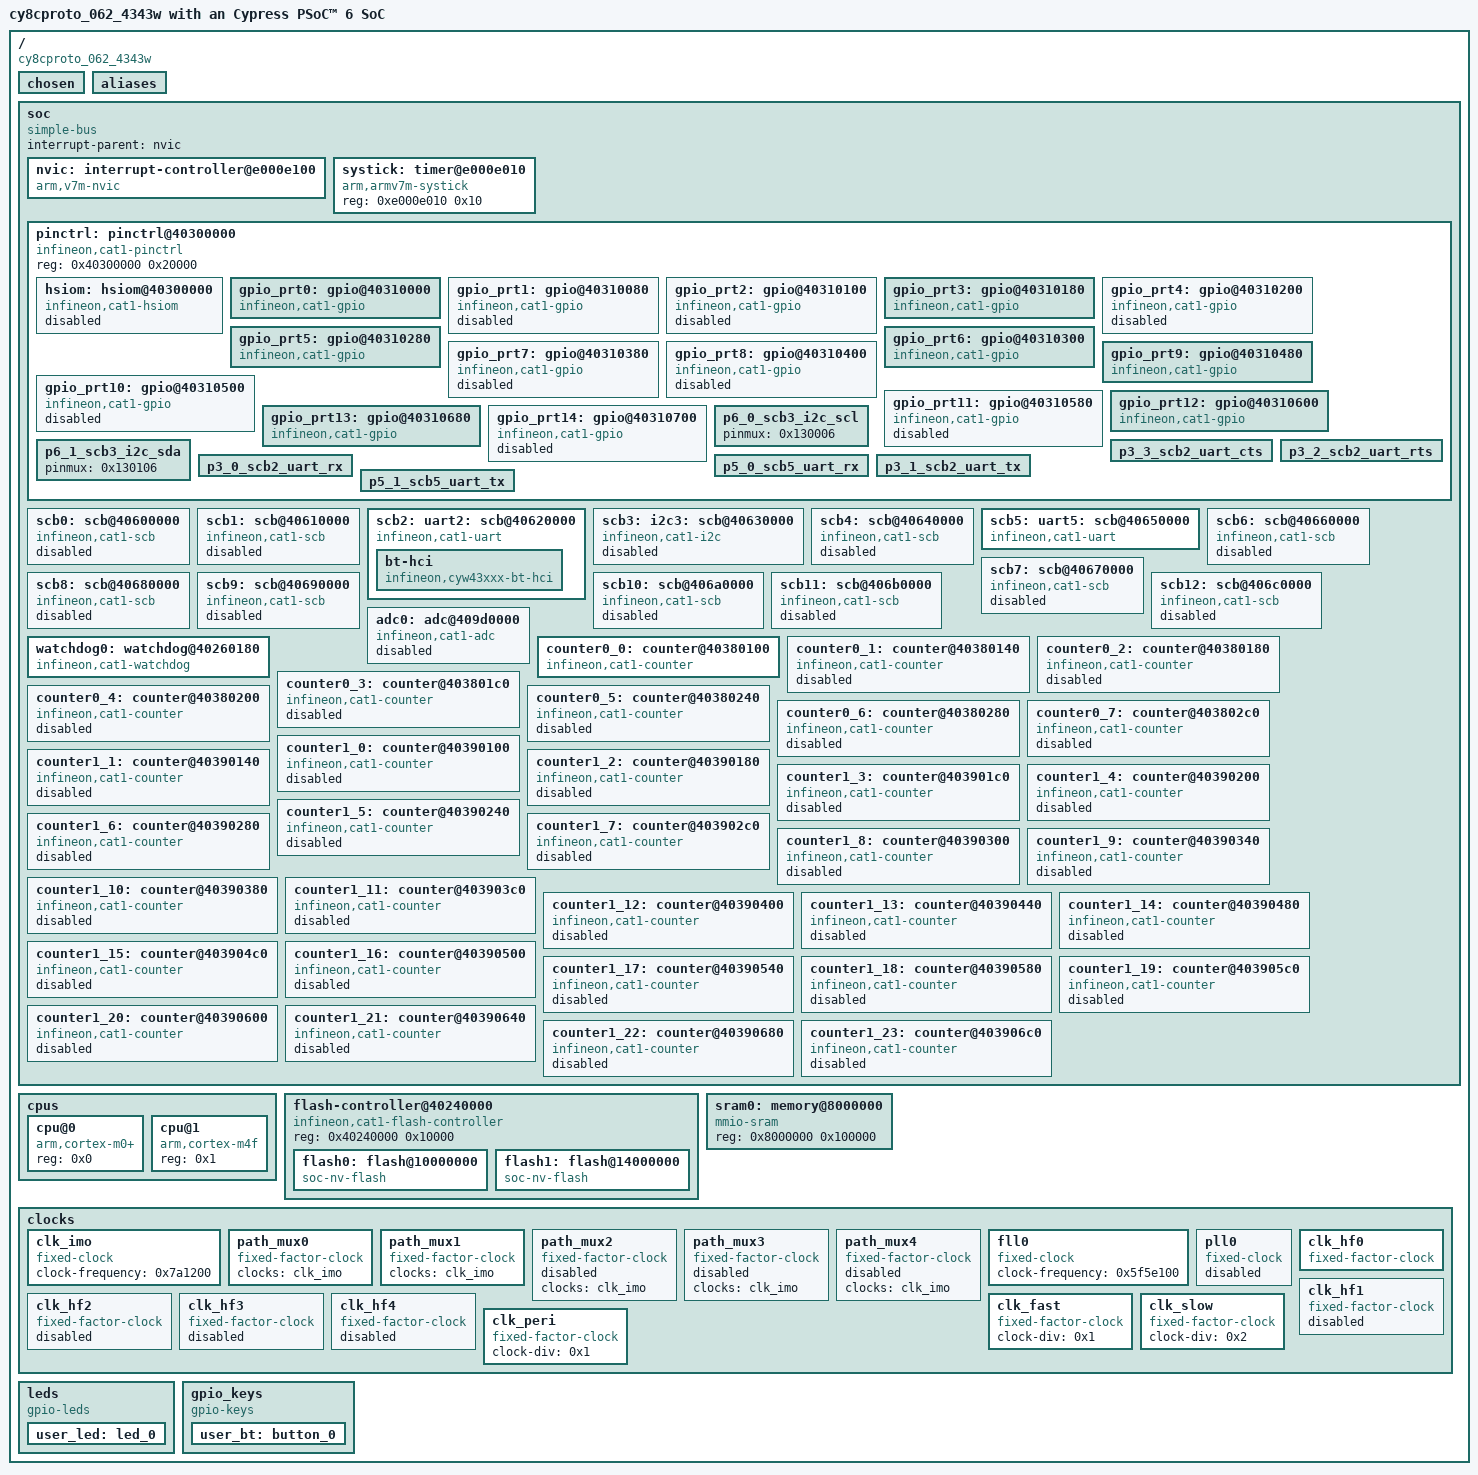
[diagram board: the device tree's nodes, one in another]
/dts-v1/;

/ {
	#address-cells = < 0x1 >;
	#size-cells = < 0x1 >;
	model = "cy8cproto_062_4343w with an Cypress PSoC™ 6 SoC";
	compatible = "cy8cproto_062_4343w", "PSoC6";
	chosen {
		zephyr,sram = &sram0;
		zephyr,flash = &flash0;
		zephyr,console = &uart5;
		zephyr,shell-uart = &uart5;
		zephyr,bt_uart = &uart2;
	};
	aliases {
		led0 = &user_led;
		sw0 = &user_bt;
		uart-5 = &uart5;
		i2c-0 = &i2c3;
		watchdog0 = &watchdog0;
	};
	soc {
		#address-cells = < 0x1 >;
		#size-cells = < 0x1 >;
		compatible = "simple-bus";
		interrupt-parent = < &nvic >;
		ranges;
		nvic: interrupt-controller@e000e100 {
			#address-cells = < 0x1 >;
			compatible = "arm,v7m-nvic";
			reg = < 0xe000e100 0xc00 >;
			interrupt-controller;
			#interrupt-cells = < 0x2 >;
			arm,num-irq-priority-bits = < 0x3 >;
			phandle = < 0x1 >;
		};
		systick: timer@e000e010 {
			compatible = "arm,armv7m-systick";
			reg = < 0xe000e010 0x10 >;
		};
		pinctrl: pinctrl@40300000 {
			compatible = "infineon,cat1-pinctrl";
			reg = < 0x40300000 0x20000 >;
			#address-cells = < 0x1 >;
			#size-cells = < 0x0 >;
			hsiom: hsiom@40300000 {
				compatible = "infineon,cat1-hsiom";
				reg = < 0x40300000 0x4000 >;
				interrupts = < 0xf 0x6 >, < 0x10 0x6 >;
				status = "disabled";
			};
			gpio_prt0: gpio@40310000 {
				compatible = "infineon,cat1-gpio";
				reg = < 0x40310000 0x80 >;
				interrupts = < 0x0 0x6 >;
				gpio-controller;
				ngpios = < 0x6 >;
				status = "okay";
				#gpio-cells = < 0x2 >;
				phandle = < 0x12 >;
			};
			gpio_prt1: gpio@40310080 {
				compatible = "infineon,cat1-gpio";
				reg = < 0x40310080 0x80 >;
				interrupts = < 0x1 0x6 >;
				gpio-controller;
				ngpios = < 0x6 >;
				status = "disabled";
				#gpio-cells = < 0x2 >;
			};
			gpio_prt2: gpio@40310100 {
				compatible = "infineon,cat1-gpio";
				reg = < 0x40310100 0x80 >;
				interrupts = < 0x2 0x6 >;
				gpio-controller;
				ngpios = < 0x8 >;
				status = "disabled";
				#gpio-cells = < 0x2 >;
			};
			gpio_prt3: gpio@40310180 {
				compatible = "infineon,cat1-gpio";
				reg = < 0x40310180 0x80 >;
				interrupts = < 0x3 0x6 >;
				gpio-controller;
				ngpios = < 0x6 >;
				status = "okay";
				#gpio-cells = < 0x2 >;
				phandle = < 0x6 >;
			};
			gpio_prt4: gpio@40310200 {
				compatible = "infineon,cat1-gpio";
				reg = < 0x40310200 0x80 >;
				interrupts = < 0x4 0x6 >;
				gpio-controller;
				ngpios = < 0x2 >;
				status = "disabled";
				#gpio-cells = < 0x2 >;
			};
			gpio_prt5: gpio@40310280 {
				compatible = "infineon,cat1-gpio";
				reg = < 0x40310280 0x80 >;
				interrupts = < 0x5 0x6 >;
				gpio-controller;
				ngpios = < 0x8 >;
				status = "okay";
				#gpio-cells = < 0x2 >;
			};
			gpio_prt6: gpio@40310300 {
				compatible = "infineon,cat1-gpio";
				reg = < 0x40310300 0x80 >;
				interrupts = < 0x6 0x6 >;
				gpio-controller;
				ngpios = < 0x8 >;
				status = "okay";
				#gpio-cells = < 0x2 >;
			};
			gpio_prt7: gpio@40310380 {
				compatible = "infineon,cat1-gpio";
				reg = < 0x40310380 0x80 >;
				interrupts = < 0x7 0x6 >;
				gpio-controller;
				ngpios = < 0x8 >;
				status = "disabled";
				#gpio-cells = < 0x2 >;
			};
			gpio_prt8: gpio@40310400 {
				compatible = "infineon,cat1-gpio";
				reg = < 0x40310400 0x80 >;
				interrupts = < 0x8 0x6 >;
				gpio-controller;
				ngpios = < 0x8 >;
				status = "disabled";
				#gpio-cells = < 0x2 >;
			};
			gpio_prt9: gpio@40310480 {
				compatible = "infineon,cat1-gpio";
				reg = < 0x40310480 0x80 >;
				interrupts = < 0x9 0x6 >;
				gpio-controller;
				ngpios = < 0x8 >;
				status = "okay";
				#gpio-cells = < 0x2 >;
			};
			gpio_prt10: gpio@40310500 {
				compatible = "infineon,cat1-gpio";
				reg = < 0x40310500 0x80 >;
				interrupts = < 0xa 0x6 >;
				gpio-controller;
				ngpios = < 0x8 >;
				status = "disabled";
				#gpio-cells = < 0x2 >;
			};
			gpio_prt11: gpio@40310580 {
				compatible = "infineon,cat1-gpio";
				reg = < 0x40310580 0x80 >;
				interrupts = < 0xb 0x6 >;
				gpio-controller;
				ngpios = < 0x8 >;
				status = "disabled";
				#gpio-cells = < 0x2 >;
			};
			gpio_prt12: gpio@40310600 {
				compatible = "infineon,cat1-gpio";
				reg = < 0x40310600 0x80 >;
				interrupts = < 0xc 0x6 >;
				gpio-controller;
				ngpios = < 0x8 >;
				status = "okay";
				#gpio-cells = < 0x2 >;
			};
			gpio_prt13: gpio@40310680 {
				compatible = "infineon,cat1-gpio";
				reg = < 0x40310680 0x80 >;
				interrupts = < 0xd 0x6 >;
				gpio-controller;
				ngpios = < 0x8 >;
				status = "okay";
				#gpio-cells = < 0x2 >;
				phandle = < 0x11 >;
			};
			gpio_prt14: gpio@40310700 {
				compatible = "infineon,cat1-gpio";
				reg = < 0x40310700 0x80 >;
				interrupts = < 0xe 0x6 >;
				gpio-controller;
				ngpios = < 0x2 >;
				status = "disabled";
				#gpio-cells = < 0x2 >;
			};
			p6_0_scb3_i2c_scl: p6_0_scb3_i2c_scl {
				pinmux = < 0x130006 >;
				phandle = < 0x7 >;
			};
			p6_1_scb3_i2c_sda: p6_1_scb3_i2c_sda {
				pinmux = < 0x130106 >;
				phandle = < 0x8 >;
			};
			p3_3_scb2_uart_cts: p3_3_scb2_uart_cts {
				pinmux = < 0x120303 >;
				input-enable;
				phandle = < 0x5 >;
			};
			p3_2_scb2_uart_rts: p3_2_scb2_uart_rts {
				pinmux = < 0x120203 >;
				drive-push-pull;
				phandle = < 0x4 >;
			};
			p3_0_scb2_uart_rx: p3_0_scb2_uart_rx {
				pinmux = < 0x120003 >;
				input-enable;
				phandle = < 0x3 >;
			};
			p5_0_scb5_uart_rx: p5_0_scb5_uart_rx {
				pinmux = < 0x120005 >;
				input-enable;
				phandle = < 0xa >;
			};
			p3_1_scb2_uart_tx: p3_1_scb2_uart_tx {
				pinmux = < 0x120103 >;
				drive-push-pull;
				phandle = < 0x2 >;
			};
			p5_1_scb5_uart_tx: p5_1_scb5_uart_tx {
				pinmux = < 0x120105 >;
				drive-push-pull;
				phandle = < 0x9 >;
			};
		};
		scb0: scb@40600000 {
			compatible = "infineon,cat1-scb";
			reg = < 0x40600000 0x10000 >;
			#address-cells = < 0x1 >;
			#size-cells = < 0x0 >;
			interrupts = < 0x27 0x6 >;
			status = "disabled";
		};
		scb1: scb@40610000 {
			compatible = "infineon,cat1-scb";
			reg = < 0x40610000 0x10000 >;
			#address-cells = < 0x1 >;
			#size-cells = < 0x0 >;
			interrupts = < 0x28 0x6 >;
			status = "disabled";
		};
		scb2: uart2: scb@40620000 {
			compatible = "infineon,cat1-uart";
			reg = < 0x40620000 0x10000 >;
			#address-cells = < 0x1 >;
			#size-cells = < 0x0 >;
			interrupts = < 0x29 0x6 >;
			status = "okay";
			current-speed = < 0x1c200 >;
			pinctrl-0 = < &p3_1_scb2_uart_tx &p3_0_scb2_uart_rx &p3_2_scb2_uart_rts &p3_3_scb2_uart_cts >;
			pinctrl-names = "default";
			bt-hci {
				status = "okay";
				compatible = "infineon,cyw43xxx-bt-hci";
				bt-reg-on-gpios = < &gpio_prt3 0x4 0x0 >;
				fw-download-speed = < 0x2dc6c0 >;
			};
		};
		scb3: i2c3: scb@40630000 {
			compatible = "infineon,cat1-i2c";
			reg = < 0x40630000 0x10000 >;
			#address-cells = < 0x1 >;
			#size-cells = < 0x0 >;
			interrupts = < 0x2a 0x6 >;
			status = "disabled";
			pinctrl-0 = < &p6_0_scb3_i2c_scl &p6_1_scb3_i2c_sda >;
			pinctrl-names = "default";
		};
		scb4: scb@40640000 {
			compatible = "infineon,cat1-scb";
			reg = < 0x40640000 0x10000 >;
			#address-cells = < 0x1 >;
			#size-cells = < 0x0 >;
			interrupts = < 0x2b 0x6 >;
			status = "disabled";
		};
		scb5: uart5: scb@40650000 {
			compatible = "infineon,cat1-uart";
			reg = < 0x40650000 0x10000 >;
			#address-cells = < 0x1 >;
			#size-cells = < 0x0 >;
			interrupts = < 0x2c 0x6 >;
			status = "okay";
			current-speed = < 0x1c200 >;
			pinctrl-0 = < &p5_1_scb5_uart_tx &p5_0_scb5_uart_rx >;
			pinctrl-names = "default";
		};
		scb6: scb@40660000 {
			compatible = "infineon,cat1-scb";
			reg = < 0x40660000 0x10000 >;
			#address-cells = < 0x1 >;
			#size-cells = < 0x0 >;
			interrupts = < 0x2d 0x6 >;
			status = "disabled";
		};
		scb7: scb@40670000 {
			compatible = "infineon,cat1-scb";
			reg = < 0x40670000 0x10000 >;
			#address-cells = < 0x1 >;
			#size-cells = < 0x0 >;
			interrupts = < 0x2e 0x6 >;
			status = "disabled";
		};
		scb8: scb@40680000 {
			compatible = "infineon,cat1-scb";
			reg = < 0x40680000 0x10000 >;
			#address-cells = < 0x1 >;
			#size-cells = < 0x0 >;
			interrupts = < 0x12 0x6 >;
			status = "disabled";
		};
		scb9: scb@40690000 {
			compatible = "infineon,cat1-scb";
			reg = < 0x40690000 0x10000 >;
			#address-cells = < 0x1 >;
			#size-cells = < 0x0 >;
			interrupts = < 0x2f 0x6 >;
			status = "disabled";
		};
		scb10: scb@406a0000 {
			compatible = "infineon,cat1-scb";
			reg = < 0x406a0000 0x10000 >;
			#address-cells = < 0x1 >;
			#size-cells = < 0x0 >;
			interrupts = < 0x30 0x6 >;
			status = "disabled";
		};
		scb11: scb@406b0000 {
			compatible = "infineon,cat1-scb";
			reg = < 0x406b0000 0x10000 >;
			#address-cells = < 0x1 >;
			#size-cells = < 0x0 >;
			interrupts = < 0x31 0x6 >;
			status = "disabled";
		};
		scb12: scb@406c0000 {
			compatible = "infineon,cat1-scb";
			reg = < 0x406c0000 0x10000 >;
			#address-cells = < 0x1 >;
			#size-cells = < 0x0 >;
			interrupts = < 0x32 0x6 >;
			status = "disabled";
		};
		adc0: adc@409d0000 {
			compatible = "infineon,cat1-adc";
			reg = < 0x409d0000 0x10000 >;
			interrupts = < 0x9b 0x6 >;
			status = "disabled";
			#io-channel-cells = < 0x1 >;
		};
		watchdog0: watchdog@40260180 {
			compatible = "infineon,cat1-watchdog";
			reg = < 0x40260180 0xc >;
			interrupts = < 0x16 0x6 >;
			status = "okay";
		};
		counter0_0: counter@40380100 {
			compatible = "infineon,cat1-counter";
			reg = < 0x40380100 0x40 >;
			interrupts = < 0x7b 0x6 >;
			resolution = < 0x20 >;
			status = "okay";
		};
		counter0_1: counter@40380140 {
			compatible = "infineon,cat1-counter";
			reg = < 0x40380140 0x40 >;
			interrupts = < 0x7c 0x6 >;
			resolution = < 0x20 >;
			status = "disabled";
		};
		counter0_2: counter@40380180 {
			compatible = "infineon,cat1-counter";
			reg = < 0x40380180 0x40 >;
			interrupts = < 0x7d 0x6 >;
			resolution = < 0x20 >;
			status = "disabled";
		};
		counter0_3: counter@403801c0 {
			compatible = "infineon,cat1-counter";
			reg = < 0x403801c0 0x40 >;
			interrupts = < 0x7e 0x6 >;
			resolution = < 0x20 >;
			status = "disabled";
		};
		counter0_4: counter@40380200 {
			compatible = "infineon,cat1-counter";
			reg = < 0x40380200 0x40 >;
			interrupts = < 0x7f 0x6 >;
			resolution = < 0x20 >;
			status = "disabled";
		};
		counter0_5: counter@40380240 {
			compatible = "infineon,cat1-counter";
			reg = < 0x40380240 0x40 >;
			interrupts = < 0x80 0x6 >;
			resolution = < 0x20 >;
			status = "disabled";
		};
		counter0_6: counter@40380280 {
			compatible = "infineon,cat1-counter";
			reg = < 0x40380280 0x40 >;
			interrupts = < 0x81 0x6 >;
			resolution = < 0x20 >;
			status = "disabled";
		};
		counter0_7: counter@403802c0 {
			compatible = "infineon,cat1-counter";
			reg = < 0x403802c0 0x40 >;
			interrupts = < 0x82 0x6 >;
			resolution = < 0x20 >;
			status = "disabled";
		};
		counter1_0: counter@40390100 {
			compatible = "infineon,cat1-counter";
			reg = < 0x40390100 0x40 >;
			interrupts = < 0x83 0x6 >;
			resolution = < 0x10 >;
			status = "disabled";
		};
		counter1_1: counter@40390140 {
			compatible = "infineon,cat1-counter";
			reg = < 0x40390140 0x40 >;
			interrupts = < 0x84 0x6 >;
			resolution = < 0x10 >;
			status = "disabled";
		};
		counter1_2: counter@40390180 {
			compatible = "infineon,cat1-counter";
			reg = < 0x40390180 0x40 >;
			interrupts = < 0x85 0x6 >;
			resolution = < 0x10 >;
			status = "disabled";
		};
		counter1_3: counter@403901c0 {
			compatible = "infineon,cat1-counter";
			reg = < 0x403901c0 0x40 >;
			interrupts = < 0x86 0x6 >;
			resolution = < 0x10 >;
			status = "disabled";
		};
		counter1_4: counter@40390200 {
			compatible = "infineon,cat1-counter";
			reg = < 0x40390200 0x40 >;
			interrupts = < 0x87 0x6 >;
			resolution = < 0x10 >;
			status = "disabled";
		};
		counter1_5: counter@40390240 {
			compatible = "infineon,cat1-counter";
			reg = < 0x40390240 0x40 >;
			interrupts = < 0x88 0x6 >;
			resolution = < 0x10 >;
			status = "disabled";
		};
		counter1_6: counter@40390280 {
			compatible = "infineon,cat1-counter";
			reg = < 0x40390280 0x40 >;
			interrupts = < 0x89 0x6 >;
			resolution = < 0x10 >;
			status = "disabled";
		};
		counter1_7: counter@403902c0 {
			compatible = "infineon,cat1-counter";
			reg = < 0x403902c0 0x40 >;
			interrupts = < 0x8a 0x6 >;
			resolution = < 0x10 >;
			status = "disabled";
		};
		counter1_8: counter@40390300 {
			compatible = "infineon,cat1-counter";
			reg = < 0x40390300 0x40 >;
			interrupts = < 0x8b 0x6 >;
			resolution = < 0x10 >;
			status = "disabled";
		};
		counter1_9: counter@40390340 {
			compatible = "infineon,cat1-counter";
			reg = < 0x40390340 0x40 >;
			interrupts = < 0x8c 0x6 >;
			resolution = < 0x10 >;
			status = "disabled";
		};
		counter1_10: counter@40390380 {
			compatible = "infineon,cat1-counter";
			reg = < 0x40390380 0x40 >;
			interrupts = < 0x8d 0x6 >;
			resolution = < 0x10 >;
			status = "disabled";
		};
		counter1_11: counter@403903c0 {
			compatible = "infineon,cat1-counter";
			reg = < 0x403903c0 0x40 >;
			interrupts = < 0x8e 0x6 >;
			resolution = < 0x10 >;
			status = "disabled";
		};
		counter1_12: counter@40390400 {
			compatible = "infineon,cat1-counter";
			reg = < 0x40390400 0x40 >;
			interrupts = < 0x8f 0x6 >;
			resolution = < 0x10 >;
			status = "disabled";
		};
		counter1_13: counter@40390440 {
			compatible = "infineon,cat1-counter";
			reg = < 0x40390440 0x40 >;
			interrupts = < 0x90 0x6 >;
			resolution = < 0x10 >;
			status = "disabled";
		};
		counter1_14: counter@40390480 {
			compatible = "infineon,cat1-counter";
			reg = < 0x40390480 0x40 >;
			interrupts = < 0x91 0x6 >;
			resolution = < 0x10 >;
			status = "disabled";
		};
		counter1_15: counter@403904c0 {
			compatible = "infineon,cat1-counter";
			reg = < 0x403904c0 0x40 >;
			interrupts = < 0x92 0x6 >;
			resolution = < 0x10 >;
			status = "disabled";
		};
		counter1_16: counter@40390500 {
			compatible = "infineon,cat1-counter";
			reg = < 0x40390500 0x40 >;
			interrupts = < 0x93 0x6 >;
			resolution = < 0x10 >;
			status = "disabled";
		};
		counter1_17: counter@40390540 {
			compatible = "infineon,cat1-counter";
			reg = < 0x40390540 0x40 >;
			interrupts = < 0x94 0x6 >;
			resolution = < 0x10 >;
			status = "disabled";
		};
		counter1_18: counter@40390580 {
			compatible = "infineon,cat1-counter";
			reg = < 0x40390580 0x40 >;
			interrupts = < 0x95 0x6 >;
			resolution = < 0x10 >;
			status = "disabled";
		};
		counter1_19: counter@403905c0 {
			compatible = "infineon,cat1-counter";
			reg = < 0x403905c0 0x40 >;
			interrupts = < 0x96 0x6 >;
			resolution = < 0x10 >;
			status = "disabled";
		};
		counter1_20: counter@40390600 {
			compatible = "infineon,cat1-counter";
			reg = < 0x40390600 0x40 >;
			interrupts = < 0x97 0x6 >;
			resolution = < 0x10 >;
			status = "disabled";
		};
		counter1_21: counter@40390640 {
			compatible = "infineon,cat1-counter";
			reg = < 0x40390640 0x40 >;
			interrupts = < 0x98 0x6 >;
			resolution = < 0x10 >;
			status = "disabled";
		};
		counter1_22: counter@40390680 {
			compatible = "infineon,cat1-counter";
			reg = < 0x40390680 0x40 >;
			interrupts = < 0x99 0x6 >;
			resolution = < 0x10 >;
			status = "disabled";
		};
		counter1_23: counter@403906c0 {
			compatible = "infineon,cat1-counter";
			reg = < 0x403906c0 0x40 >;
			interrupts = < 0x9a 0x6 >;
			resolution = < 0x10 >;
			status = "disabled";
		};
	};
	cpus {
		#address-cells = < 0x1 >;
		#size-cells = < 0x0 >;
		cpu@0 {
			device_type = "cpu";
			compatible = "arm,cortex-m0+";
			reg = < 0x0 >;
		};
		cpu@1 {
			device_type = "cpu";
			compatible = "arm,cortex-m4f";
			reg = < 0x1 >;
		};
	};
	flash-controller@40240000 {
		compatible = "infineon,cat1-flash-controller";
		reg = < 0x40240000 0x10000 >;
		#address-cells = < 0x1 >;
		#size-cells = < 0x1 >;
		flash0: flash@10000000 {
			compatible = "soc-nv-flash";
			reg = < 0x10000000 0x200000 >;
			write-block-size = < 0x200 >;
			erase-block-size = < 0x200 >;
		};
		flash1: flash@14000000 {
			compatible = "soc-nv-flash";
			reg = < 0x14000000 0x8000 >;
			write-block-size = < 0x200 >;
			erase-block-size = < 0x200 >;
		};
	};
	sram0: memory@8000000 {
		compatible = "mmio-sram";
		reg = < 0x8000000 0x100000 >;
	};
	clocks {
		clk_imo: clk_imo {
			#clock-cells = < 0x0 >;
			compatible = "fixed-clock";
			clock-frequency = < 0x7a1200 >;
			status = "okay";
			phandle = < 0xb >;
		};
		path_mux0: path_mux0 {
			#clock-cells = < 0x0 >;
			compatible = "fixed-factor-clock";
			clocks = < &clk_imo >;
			status = "okay";
		};
		path_mux1: path_mux1 {
			#clock-cells = < 0x0 >;
			compatible = "fixed-factor-clock";
			clocks = < &clk_imo >;
			status = "okay";
			phandle = < 0xd >;
		};
		path_mux2: path_mux2 {
			#clock-cells = < 0x0 >;
			compatible = "fixed-factor-clock";
			clocks = < &clk_imo >;
			status = "disabled";
			phandle = < 0xe >;
		};
		path_mux3: path_mux3 {
			#clock-cells = < 0x0 >;
			compatible = "fixed-factor-clock";
			clocks = < &clk_imo >;
			status = "disabled";
			phandle = < 0xf >;
		};
		path_mux4: path_mux4 {
			#clock-cells = < 0x0 >;
			compatible = "fixed-factor-clock";
			clocks = < &clk_imo >;
			status = "disabled";
			phandle = < 0x10 >;
		};
		fll0: fll0 {
			#clock-cells = < 0x0 >;
			compatible = "fixed-clock";
			status = "okay";
			clock-frequency = < 0x5f5e100 >;
			phandle = < 0xc >;
		};
		pll0: pll0 {
			#clock-cells = < 0x0 >;
			compatible = "fixed-clock";
			status = "disabled";
		};
		clk_hf0: clk_hf0 {
			#clock-cells = < 0x0 >;
			compatible = "fixed-factor-clock";
			clock-div = < 0x1 >;
			clocks = < &fll0 >;
			status = "okay";
		};
		clk_hf1: clk_hf1 {
			#clock-cells = < 0x0 >;
			compatible = "fixed-factor-clock";
			clock-div = < 0x1 >;
			clocks = < &path_mux1 >;
			status = "disabled";
		};
		clk_hf2: clk_hf2 {
			#clock-cells = < 0x0 >;
			compatible = "fixed-factor-clock";
			clock-div = < 0x1 >;
			clocks = < &path_mux2 >;
			status = "disabled";
		};
		clk_hf3: clk_hf3 {
			#clock-cells = < 0x0 >;
			compatible = "fixed-factor-clock";
			clock-div = < 0x1 >;
			clocks = < &path_mux3 >;
			status = "disabled";
		};
		clk_hf4: clk_hf4 {
			#clock-cells = < 0x0 >;
			compatible = "fixed-factor-clock";
			clock-div = < 0x1 >;
			clocks = < &path_mux4 >;
			status = "disabled";
		};
		clk_fast: clk_fast {
			#clock-cells = < 0x0 >;
			compatible = "fixed-factor-clock";
			clock-div = < 0x1 >;
			status = "okay";
		};
		clk_slow: clk_slow {
			#clock-cells = < 0x0 >;
			compatible = "fixed-factor-clock";
			clock-div = < 0x2 >;
			status = "okay";
		};
		clk_peri: clk_peri {
			#clock-cells = < 0x0 >;
			compatible = "fixed-factor-clock";
			clock-div = < 0x1 >;
			status = "okay";
		};
	};
	leds {
		compatible = "gpio-leds";
		user_led: led_0 {
			label = "LED_0";
			gpios = < &gpio_prt13 0x7 0x0 >;
		};
	};
	gpio_keys {
		compatible = "gpio-keys";
		user_bt: button_0 {
			label = "SW_0";
			gpios = < &gpio_prt0 0x4 0x11 >;
			zephyr,code = < 0xb >;
		};
	};
};
